# MSP430FR5962 register map
File version: 2.1
CPU: MSP430FR5962 r2p1, little endian, MPU, no FPU, 3 interrupt priority bits
Registers are 16-bit, read-write, reset 0x0 unless marked. A register's access mark holds for its fields unless they carry their own. Offsets are from the block's base; [hi:lo] are bit positions; {n}, {i} and the like mark numbered series.

## P2
Base 0x00000200
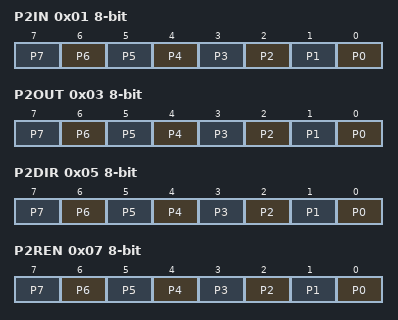
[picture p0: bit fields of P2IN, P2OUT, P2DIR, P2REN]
0x01 P2IN 8-bit — Port 2 Input
  [n] P{n} (n=0..7)
0x03 P2OUT 8-bit — Port 2 Output
  [n] P{n} (n=0..7)
0x05 P2DIR 8-bit — Port 2 Direction
  [n] P{n} (n=0..7)
0x07 P2REN 8-bit — Port 2 Resistor Enable
  [n] P{n} (n=0..7)
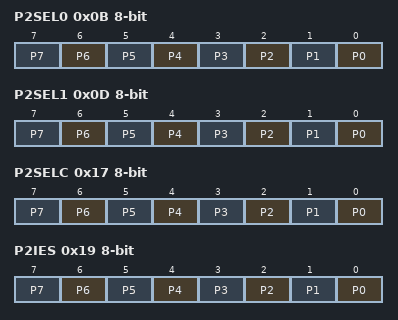
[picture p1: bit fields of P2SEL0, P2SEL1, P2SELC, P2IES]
0x0B P2SEL0 8-bit — Port 2 Select 0
  [n] P{n} (n=0..7)
0x0D P2SEL1 8-bit — Port 2 Select 1
  [n] P{n} (n=0..7)
0x17 P2SELC 8-bit — Port 2 Complement Select
  [n] P{n} (n=0..7)
0x19 P2IES 8-bit — Port 2 Interrupt Edge Select
  [n] P{n} (n=0..7)
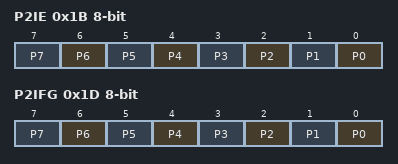
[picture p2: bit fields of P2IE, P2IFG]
0x1B P2IE 8-bit — Port 2 Interrupt Enable
  [n] P{n} (n=0..7)
0x1D P2IFG 8-bit — Port 2 Interrupt Flag
  [n] P{n} (n=0..7)
0x1E P2IV — Port 2 Interrupt Vector Register
  [4:0] P2IV — [4:0] Port 2 interrupt vector value
    0=NONE (No interrupt pending); 2=P2IFG0 (Interrupt Source: Port 2.0 interrupt; Interrupt Flag: P2IFG0; Interrupt Priority: Highest); 4=P2IFG1 (Interrupt Source: Port 2.1 interrupt; Interrupt Flag: P2IFG1); 6=P2IFG2 (Interrupt Source: Port 2.2 interrupt; Interrupt Flag: P2IFG2); 8=P2IFG3 (Interrupt Source: Port 2.3 interrupt; Interrupt Flag: P2IFG3); 10=P2IFG4 (Interrupt Source: Port 2.4 interrupt; Interrupt Flag: P2IFG4); 12=P2IFG5 (Interrupt Source: Port 2.5 interrupt; Interrupt Flag: P2IFG5); 14=P2IFG6 (Interrupt Source: Port 2.6 interrupt; Interrupt Flag: P2IFG6); 16=P2IFG7 (Interrupt Source: Port 2.7 interrupt; Interrupt Flag: P2IFG7; Interrupt Priority: Lowest)

## PB
Base 0x00000200
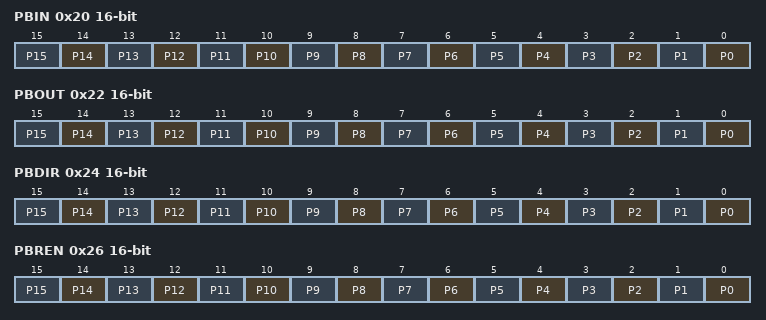
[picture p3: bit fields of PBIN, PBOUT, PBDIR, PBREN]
0x20 PBIN — Port B Input
  [n] P{n} (n=0..15)
0x22 PBOUT — Port B Output
  [n] P{n} (n=0..15)
0x24 PBDIR — Port B Direction
  [n] P{n} (n=0..15)
0x26 PBREN — Port B Resistor Enable
  [n] P{n} (n=0..15)
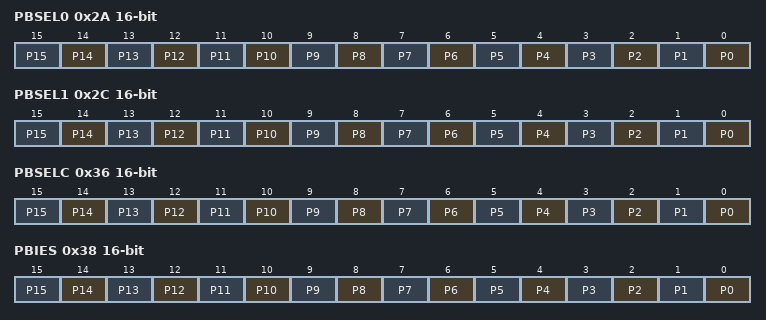
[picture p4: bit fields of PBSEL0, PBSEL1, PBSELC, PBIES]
0x2A PBSEL0 — Port B Select 0
  [n] P{n} (n=0..15)
0x2C PBSEL1 — Port B Select 1
  [n] P{n} (n=0..15)
0x36 PBSELC — Port B Complement Select
  [n] P{n} (n=0..15)
0x38 PBIES — Port B Interrupt Edge Select
  [n] P{n} (n=0..15)
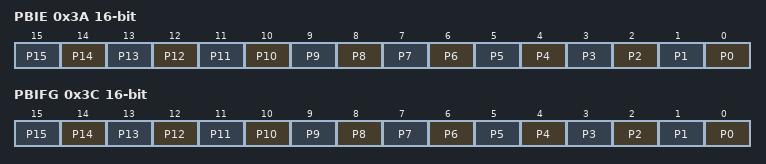
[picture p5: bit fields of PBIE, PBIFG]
0x3A PBIE — Port B Interrupt Enable
  [n] P{n} (n=0..15)
0x3C PBIFG — Port B Interrupt Flag
  [n] P{n} (n=0..15)

## P3
Base 0x00000200
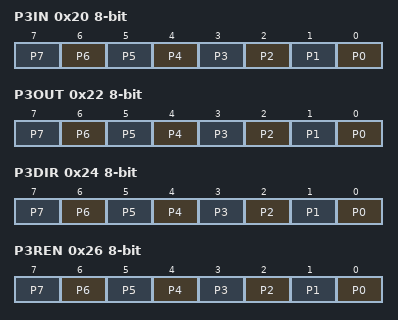
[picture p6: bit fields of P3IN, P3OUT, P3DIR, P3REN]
0x20 P3IN 8-bit — Port 3 Input
  [n] P{n} (n=0..7)
0x22 P3OUT 8-bit — Port 3 Output
  [n] P{n} (n=0..7)
0x24 P3DIR 8-bit — Port 3 Direction
  [n] P{n} (n=0..7)
0x26 P3REN 8-bit — Port 3 Resistor Enable
  [n] P{n} (n=0..7)
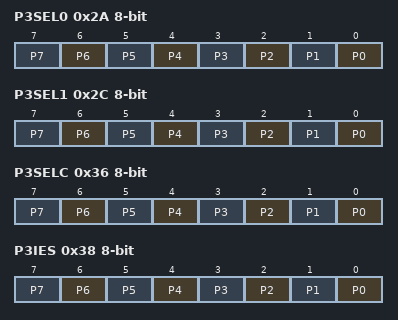
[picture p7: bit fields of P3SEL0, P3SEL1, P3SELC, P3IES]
0x2A P3SEL0 8-bit — Port 3 Select 0
  [n] P{n} (n=0..7)
0x2C P3SEL1 8-bit — Port 3 Select 1
  [n] P{n} (n=0..7)
0x2E P3IV — Port 3 Interrupt Vector Register
  [4:0] P3IV — [4:0] Port 3 interrupt vector value
    0=NONE (No interrupt pending); 2=P3IFG0 (Interrupt Source: Port 3.0 interrupt; Interrupt Flag: P3IFG0; Interrupt Priority: Highest); 4=P3IFG1 (Interrupt Source: Port 3.1 interrupt; Interrupt Flag: P3IFG1); 6=P3IFG2 (Interrupt Source: Port 3.2 interrupt; Interrupt Flag: P3IFG2); 8=P3IFG3 (Interrupt Source: Port 3.3 interrupt; Interrupt Flag: P3IFG3); 10=P3IFG4 (Interrupt Source: Port 3.4 interrupt; Interrupt Flag: P3IFG4); 12=P3IFG5 (Interrupt Source: Port 3.5 interrupt; Interrupt Flag: P3IFG5); 14=P3IFG6 (Interrupt Source: Port 3.6 interrupt; Interrupt Flag: P3IFG6); 16=P3IFG7 (Interrupt Source: Port 3.7 interrupt; Interrupt Flag: P3IFG7; Interrupt Priority: Lowest)
0x36 P3SELC 8-bit — Port 3 Complement Select
  [n] P{n} (n=0..7)
0x38 P3IES 8-bit — Port 3 Interrupt Edge Select
  [n] P{n} (n=0..7)
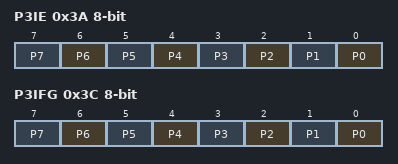
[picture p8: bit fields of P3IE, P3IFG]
0x3A P3IE 8-bit — Port 3 Interrupt Enable
  [n] P{n} (n=0..7)
0x3C P3IFG 8-bit — Port 3 Interrupt Flag
  [n] P{n} (n=0..7)

## P4
Base 0x00000200
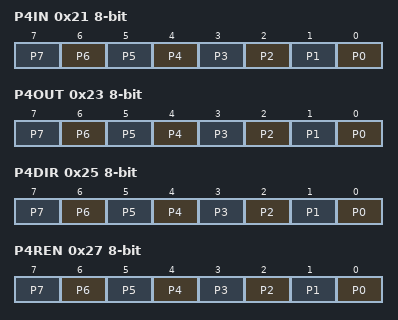
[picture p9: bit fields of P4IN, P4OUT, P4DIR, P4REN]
0x21 P4IN 8-bit — Port 4 Input
  [n] P{n} (n=0..7)
0x23 P4OUT 8-bit — Port 4 Output
  [n] P{n} (n=0..7)
0x25 P4DIR 8-bit — Port 4 Direction
  [n] P{n} (n=0..7)
0x27 P4REN 8-bit — Port 4 Resistor Enable
  [n] P{n} (n=0..7)
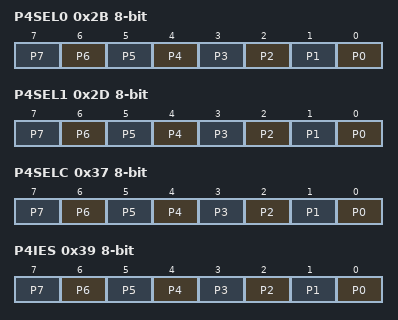
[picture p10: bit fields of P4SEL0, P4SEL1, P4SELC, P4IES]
0x2B P4SEL0 8-bit — Port 4 Select 0
  [n] P{n} (n=0..7)
0x2D P4SEL1 8-bit — Port 4 Select 1
  [n] P{n} (n=0..7)
0x37 P4SELC 8-bit — Port 4 Complement Select
  [n] P{n} (n=0..7)
0x39 P4IES 8-bit — Port 4 Interrupt Edge Select
  [n] P{n} (n=0..7)
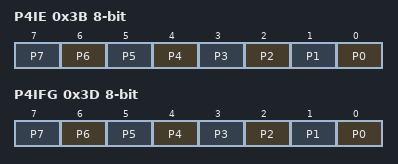
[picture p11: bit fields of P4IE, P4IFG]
0x3B P4IE 8-bit — Port 4 Interrupt Enable
  [n] P{n} (n=0..7)
0x3D P4IFG 8-bit — Port 4 Interrupt Flag
  [n] P{n} (n=0..7)
0x3E P4IV — Port 4 Interrupt Vector Register
  [4:0] P4IV — [4:0] Port 4 interrupt vector value
    0=NONE (No interrupt pending); 2=P4IFG0 (Interrupt Source: Port 4.0 interrupt; Interrupt Flag: P4IFG0; Interrupt Priority: Highest); 4=P4IFG1 (Interrupt Source: Port 4.1 interrupt; Interrupt Flag: P4IFG1); 6=P4IFG2 (Interrupt Source: Port 4.2 interrupt; Interrupt Flag: P4IFG2); 8=P4IFG3 (Interrupt Source: Port 4.3 interrupt; Interrupt Flag: P4IFG3); 10=P4IFG4 (Interrupt Source: Port 4.4 interrupt; Interrupt Flag: P4IFG4); 12=P4IFG5 (Interrupt Source: Port 4.5 interrupt; Interrupt Flag: P4IFG5); 14=P4IFG6 (Interrupt Source: Port 4.6 interrupt; Interrupt Flag: P4IFG6); 16=P4IFG7 (Interrupt Source: Port 4.7 interrupt; Interrupt Flag: P4IFG7; Interrupt Priority: Lowest)
